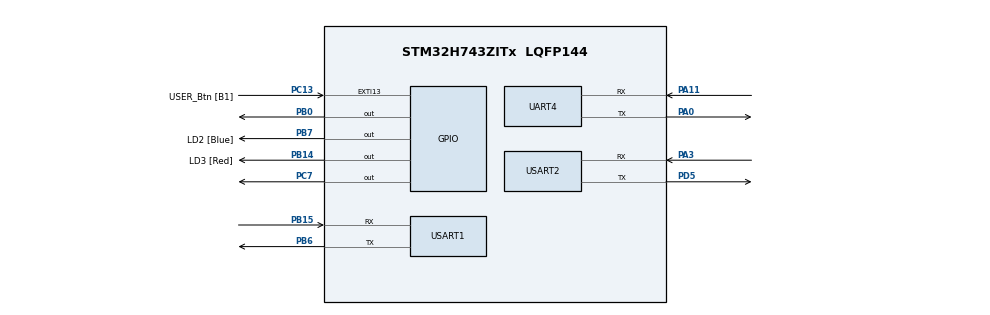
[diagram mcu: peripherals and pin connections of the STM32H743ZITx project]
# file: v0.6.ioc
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Mcu.Family=STM32H7
Mcu.Name=STM32H743ZITx
Mcu.Package=LQFP144
NVIC.PriorityGroup=NVIC_PRIORITYGROUP_4
NVIC.TIM6_DAC_IRQn=true\:0\:0\:false\:false\:true\:true\:true
NVIC.UART4_IRQn=true\:0\:0\:false\:false\:true\:true\:true
NVIC.USART1_IRQn=true\:0\:0\:false\:false\:true\:true\:true
NVIC.USART2_IRQn=true\:0\:0\:false\:false\:true\:true\:true
PA0.Mode=Asynchronous
PA0.Signal=UART4_TX
PA1.GPIO_Label=RMII_REF_CLK
PA1.Signal=ETH_REF_CLK
PA11.Mode=Asynchronous
PA11.Signal=UART4_RX
PA2.GPIO_Label=RMII_MDIO
PA2.Signal=ETH_MDIO
PA3.Mode=Asynchronous
PA3.Signal=USART2_RX
PA7.GPIO_Label=RMII_CRS_DV
PA7.Signal=ETH_CRS_DV
PB0.Signal=GPIO_Output
PB14.GPIO_Label=LD3 [Red]
PB14.Signal=GPIO_Output
PB15.Mode=Asynchronous
PB15.Signal=USART1_RX
PB6.Mode=Asynchronous
PB6.Signal=USART1_TX
PB7.GPIO_Label=LD2 [Blue]
PB7.Signal=GPIO_Output
PC1.GPIO_Label=RMII_MDC
PC1.Signal=ETH_MDC
PC13.GPIO_Label=USER_Btn [B1]
PC13.Signal=GPXTI13
PC14-OSC32_IN\ (OSC32_IN).Mode=LSE-External-Oscillator
PC14-OSC32_IN\ (OSC32_IN).Signal=RCC_OSC32_IN
PC15-OSC32_OUT\ (OSC32_OUT).Mode=LSE-External-Oscillator
PC15-OSC32_OUT\ (OSC32_OUT).Signal=RCC_OSC32_OUT
PC4.GPIO_Label=RMII_RXD0
PC4.Signal=ETH_RXD0
PC5.GPIO_Label=RMII_RXD1
PC5.Signal=ETH_RXD1
PC7.Signal=GPIO_Output
PD5.Mode=Asynchronous
PD5.Signal=USART2_TX
PD8.GPIO_Label=STLK_RX [STM32F103CBT6_PA3]
PD8.Signal=USART3_TX
PD9.GPIO_Label=STLK_TX [STM32F103CBT6_PA2]
PD9.Signal=USART3_RX
PG11.GPIO_Label=RMII_TX_EN
PG11.Signal=ETH_TX_EN
PG13.GPIO_Label=RMII_TXD0
PG13.Signal=ETH_TXD0
PH0-OSC_IN\ (PH0).GPIO_Label=MCO
PH0-OSC_IN\ (PH0).Mode=HSE-External-Clock-Source
PH0-OSC_IN\ (PH0).Signal=RCC_OSC_IN
PH1-OSC_OUT\ (PH1).Mode=HSE-External-Clock-Source
PH1-OSC_OUT\ (PH1).Signal=RCC_OSC_OUT
ProjectManager.HeapSize=0x200
ProjectManager.StackSize=0x400
ProjectManager.TargetToolchain=STM32CubeIDE
RCC.48MHZClocksFreq_Value=24000000
RCC.ADCFreq_Value=16125000
RCC.AHBFreq_Value=216000000
RCC.APB1CLKDivider=RCC_HCLK_DIV4
RCC.APB1Freq_Value=120000000
RCC.APB1TimFreq_Value=108000000
RCC.APB2CLKDivider=RCC_HCLK_DIV2
RCC.APB2Freq_Value=120000000
RCC.APB2TimFreq_Value=216000000
RCC.APB3Freq_Value=120000000
RCC.APB4Freq_Value=120000000
RCC.CortexFreq_Value=480000000
RCC.D1PPRE=RCC_APB3_DIV2
RCC.D2PPRE1=RCC_APB1_DIV2
RCC.D2PPRE2=RCC_APB2_DIV2
RCC.D3PPRE=RCC_APB4_DIV2
RCC.DIVM1=1
RCC.DIVN1=120
RCC.DIVQ1=20
RCC.HCLKFreq_Value=240000000
RCC.HPRE=RCC_HCLK_DIV2
RCC.HSE_VALUE=8000000
RCC.HSI_VALUE=64000000
RCC.PLLFRACN=0
RCC.PLLM=25
RCC.PLLMUL=RCC_PLL_MUL9
RCC.PLLN=432
RCC.PLLQ=9
RCC.PLLSourceVirtual=RCC_PLLSOURCE_HSE
RCC.PRESCALERUSB=RCC_USBCLKSOURCE_PLL_DIV1_5
RCC.PWR_Regulator_Voltage_Scale=PWR_REGULATOR_VOLTAGE_SCALE1
RCC.SYSCLKFreq_VALUE=480000000
RCC.SYSCLKSource=RCC_SYSCLKSOURCE_PLLCLK
RCC.SYSCLKSourceVirtual=RCC_SYSCLKSOURCE_PLLCLK
RCC.USBFreq_Value=48000000
RCC.VCOOutputFreq_Value=432000000
TIM6.Period=1
TIM6.Prescaler=12000
TIM6.TIM_MasterOutputTrigger=TIM_TRGO_UPDATE
USART1.VirtualMode-Asynchronous=VM_ASYNC
USART2.VirtualMode-Asynchronous=VM_ASYNC
VP_TIM6_VS_ClockSourceINT.Mode=Enable_Timer
board=NUCLEO-H743ZI

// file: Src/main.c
/* USER CODE BEGIN Header */
/**
 ******************************************************************************
 * @file           : main.c
 * @brief          : Main program body
 ******************************************************************************
 * @attention
 *
 * <h2><center>&copy; Copyright (c) 2019 STMicroelectronics.
 * All rights reserved.</center></h2>
 *
 * This software component is licensed by ST under BSD 3-Clause license,
 * the "License"; You may not use this file except in compliance with the
 * License. You may obtain a copy of the License at:
 *                        opensource.org/licenses/BSD-3-Clause
 *
 ******************************************************************************
 */
/* USER CODE END Header */

#include "main.h"

/* USER CODE BEGIN Includes */
#include "main_task.h"

/* USER CODE END Includes */

TIM_HandleTypeDef htim6;

UART_HandleTypeDef huart4;
UART_HandleTypeDef huart1;
UART_HandleTypeDef huart2;

void SystemClock_Config(void);
static void MX_GPIO_Init(void);
static void MX_TIM6_Init(void);
static void MX_USART1_UART_Init(void);
static void MX_USART2_UART_Init(void);
static void MX_UART4_Init(void);

int main(void)
{

	/* MCU Configuration--------------------------------------------------------*/

	/* Reset of all peripherals, Initializes the Flash interface and the Systick. */
	HAL_Init();

	/* Configure the system clock */
	SystemClock_Config();

	/* Initialize all configured peripherals */
	MX_GPIO_Init();
	MX_TIM6_Init();
	MX_USART1_UART_Init();
	MX_USART2_UART_Init();
	MX_UART4_Init();
	/* USER CODE BEGIN 2 */

	HAL_TIM_Base_Start_IT(&htim6);

	main_ini();

	/* USER CODE END 2 */

	/* Infinite loop */
	/* USER CODE BEGIN WHILE */
	while (1)
	{
		main_task();
		/* USER CODE END WHILE */

	}
}

void SystemClock_Config(void)
{
	RCC_OscInitTypeDef RCC_OscInitStruct = {0};
	RCC_ClkInitTypeDef RCC_ClkInitStruct = {0};
	RCC_PeriphCLKInitTypeDef PeriphClkInitStruct = {0};

	/** Supply configuration update enable
	 */
	HAL_PWREx_ConfigSupply(PWR_LDO_SUPPLY);
	/** Configure the main internal regulator output voltage
	 */
	__HAL_PWR_VOLTAGESCALING_CONFIG(PWR_REGULATOR_VOLTAGE_SCALE1);

	while(!__HAL_PWR_GET_FLAG(PWR_FLAG_VOSRDY)) {}
	/** Initializes the CPU, AHB and APB busses clocks
	 */
	RCC_OscInitStruct.OscillatorType = RCC_OSCILLATORTYPE_HSE;
	RCC_OscInitStruct.HSEState = RCC_HSE_BYPASS;
	RCC_OscInitStruct.PLL.PLLState = RCC_PLL_ON;
	RCC_OscInitStruct.PLL.PLLSource = RCC_PLLSOURCE_HSE;
	RCC_OscInitStruct.PLL.PLLM = 1;
	RCC_OscInitStruct.PLL.PLLN = 120;
	RCC_OscInitStruct.PLL.PLLP = 2;
	RCC_OscInitStruct.PLL.PLLQ = 20;
	RCC_OscInitStruct.PLL.PLLR = 2;
	RCC_OscInitStruct.PLL.PLLRGE = RCC_PLL1VCIRANGE_3;
	RCC_OscInitStruct.PLL.PLLVCOSEL = RCC_PLL1VCOWIDE;
	RCC_OscInitStruct.PLL.PLLFRACN = 0;
	if (HAL_RCC_OscConfig(&RCC_OscInitStruct) != HAL_OK)
	{
		Error_Handler();
	}
	/** Initializes the CPU, AHB and APB busses clocks
	 */
	RCC_ClkInitStruct.ClockType = RCC_CLOCKTYPE_HCLK|RCC_CLOCKTYPE_SYSCLK
			|RCC_CLOCKTYPE_PCLK1|RCC_CLOCKTYPE_PCLK2
			|RCC_CLOCKTYPE_D3PCLK1|RCC_CLOCKTYPE_D1PCLK1;
	RCC_ClkInitStruct.SYSCLKSource = RCC_SYSCLKSOURCE_PLLCLK;
	RCC_ClkInitStruct.SYSCLKDivider = RCC_SYSCLK_DIV1;
	RCC_ClkInitStruct.AHBCLKDivider = RCC_HCLK_DIV2;
	RCC_ClkInitStruct.APB3CLKDivider = RCC_APB3_DIV2;
	RCC_ClkInitStruct.APB1CLKDivider = RCC_APB1_DIV2;
	RCC_ClkInitStruct.APB2CLKDivider = RCC_APB2_DIV2;
	RCC_ClkInitStruct.APB4CLKDivider = RCC_APB4_DIV2;

	if (HAL_RCC_ClockConfig(&RCC_ClkInitStruct, FLASH_LATENCY_4) != HAL_OK)
	{
		Error_Handler();
	}
	PeriphClkInitStruct.PeriphClockSelection = RCC_PERIPHCLK_USART2|RCC_PERIPHCLK_UART4
			|RCC_PERIPHCLK_USART1;
	PeriphClkInitStruct.Usart234578ClockSelection = RCC_USART234578CLKSOURCE_D2PCLK1;
	PeriphClkInitStruct.Usart16ClockSelection = RCC_USART16CLKSOURCE_D2PCLK2;
	if (HAL_RCCEx_PeriphCLKConfig(&PeriphClkInitStruct) != HAL_OK)
	{
		Error_Handler();
	}
}

static void MX_TIM6_Init(void)
{

	TIM_MasterConfigTypeDef sMasterConfig = {0};

	htim6.Instance = TIM6;
	htim6.Init.Prescaler = 12000;
	htim6.Init.CounterMode = TIM_COUNTERMODE_UP;
	htim6.Init.Period = 1;
	htim6.Init.AutoReloadPreload = TIM_AUTORELOAD_PRELOAD_DISABLE;
	if (HAL_TIM_Base_Init(&htim6) != HAL_OK)
	{
		Error_Handler();
	}
	sMasterConfig.MasterOutputTrigger = TIM_TRGO_UPDATE;
	sMasterConfig.MasterSlaveMode = TIM_MASTERSLAVEMODE_DISABLE;
	if (HAL_TIMEx_MasterConfigSynchronization(&htim6, &sMasterConfig) != HAL_OK)
	{
		Error_Handler();
	}

}

static void MX_UART4_Init(void)
{

	huart4.Instance = UART4;
	huart4.Init.BaudRate = 115200;
	huart4.Init.WordLength = UART_WORDLENGTH_8B;
	huart4.Init.StopBits = UART_STOPBITS_1;
	huart4.Init.Parity = UART_PARITY_NONE;
	huart4.Init.Mode = UART_MODE_TX_RX;
	huart4.Init.HwFlowCtl = UART_HWCONTROL_NONE;
	huart4.Init.OverSampling = UART_OVERSAMPLING_16;
	huart4.Init.OneBitSampling = UART_ONE_BIT_SAMPLE_DISABLE;
	huart4.Init.ClockPrescaler = UART_PRESCALER_DIV1;
	huart4.AdvancedInit.AdvFeatureInit = UART_ADVFEATURE_NO_INIT;
	if (HAL_UART_Init(&huart4) != HAL_OK)
	{
		Error_Handler();
	}
	if (HAL_UARTEx_SetTxFifoThreshold(&huart4, UART_TXFIFO_THRESHOLD_1_8) != HAL_OK)
	{
		Error_Handler();
	}
	if (HAL_UARTEx_SetRxFifoThreshold(&huart4, UART_RXFIFO_THRESHOLD_1_8) != HAL_OK)
	{
		Error_Handler();
	}
	if (HAL_UARTEx_DisableFifoMode(&huart4) != HAL_OK)
	{
		Error_Handler();
	}

}

static void MX_USART1_UART_Init(void)
{

	huart1.Instance = USART1;
	huart1.Init.BaudRate = 115200;
	huart1.Init.WordLength = UART_WORDLENGTH_8B;
	huart1.Init.StopBits = UART_STOPBITS_1;
	huart1.Init.Parity = UART_PARITY_NONE;
	huart1.Init.Mode = UART_MODE_TX_RX;
	huart1.Init.HwFlowCtl = UART_HWCONTROL_NONE;
	huart1.Init.OverSampling = UART_OVERSAMPLING_16;
	huart1.Init.OneBitSampling = UART_ONE_BIT_SAMPLE_DISABLE;
	huart1.Init.ClockPrescaler = UART_PRESCALER_DIV1;
	huart1.AdvancedInit.AdvFeatureInit = UART_ADVFEATURE_NO_INIT;
	if (HAL_UART_Init(&huart1) != HAL_OK)
	{
		Error_Handler();
	}
	if (HAL_UARTEx_SetTxFifoThreshold(&huart1, UART_TXFIFO_THRESHOLD_1_8) != HAL_OK)
	{
		Error_Handler();
	}
	if (HAL_UARTEx_SetRxFifoThreshold(&huart1, UART_RXFIFO_THRESHOLD_1_8) != HAL_OK)
	{
		Error_Handler();
	}
	if (HAL_UARTEx_DisableFifoMode(&huart1) != HAL_OK)
	{
		Error_Handler();
	}

}

static void MX_USART2_UART_Init(void)
{

	huart2.Instance = USART2;
	huart2.Init.BaudRate = 115200;
	huart2.Init.WordLength = UART_WORDLENGTH_8B;
	huart2.Init.StopBits = UART_STOPBITS_1;
	huart2.Init.Parity = UART_PARITY_NONE;
	huart2.Init.Mode = UART_MODE_TX_RX;
	huart2.Init.HwFlowCtl = UART_HWCONTROL_NONE;
	huart2.Init.OverSampling = UART_OVERSAMPLING_16;
	huart2.Init.OneBitSampling = UART_ONE_BIT_SAMPLE_DISABLE;
	huart2.Init.ClockPrescaler = UART_PRESCALER_DIV1;
	huart2.AdvancedInit.AdvFeatureInit = UART_ADVFEATURE_NO_INIT;
	if (HAL_UART_Init(&huart2) != HAL_OK)
	{
		Error_Handler();
	}
	if (HAL_UARTEx_SetTxFifoThreshold(&huart2, UART_TXFIFO_THRESHOLD_1_8) != HAL_OK)
	{
		Error_Handler();
	}
	if (HAL_UARTEx_SetRxFifoThreshold(&huart2, UART_RXFIFO_THRESHOLD_1_8) != HAL_OK)
	{
		Error_Handler();
	}
	if (HAL_UARTEx_DisableFifoMode(&huart2) != HAL_OK)
	{
		Error_Handler();
	}

}

static void MX_GPIO_Init(void)
{
	GPIO_InitTypeDef GPIO_InitStruct = {0};

	/* GPIO Ports Clock Enable */
	__HAL_RCC_GPIOC_CLK_ENABLE();
	__HAL_RCC_GPIOH_CLK_ENABLE();
	__HAL_RCC_GPIOA_CLK_ENABLE();
	__HAL_RCC_GPIOB_CLK_ENABLE();
	__HAL_RCC_GPIOD_CLK_ENABLE();
	__HAL_RCC_GPIOG_CLK_ENABLE();

	/*Configure GPIO pin Output Level */
	HAL_GPIO_WritePin(GPIOB, GPIO_PIN_0|LD3_Pin|LD2_Pin, GPIO_PIN_RESET);

	/*Configure GPIO pin Output Level */
	HAL_GPIO_WritePin(GPIOC, GPIO_PIN_7, GPIO_PIN_RESET);

	/*Configure GPIO pin : USER_Btn_Pin */
	GPIO_InitStruct.Pin = USER_Btn_Pin;
	GPIO_InitStruct.Mode = GPIO_MODE_IT_RISING;
	GPIO_InitStruct.Pull = GPIO_NOPULL;
	HAL_GPIO_Init(USER_Btn_GPIO_Port, &GPIO_InitStruct);

	/*Configure GPIO pins : RMII_MDC_Pin RMII_RXD0_Pin RMII_RXD1_Pin */
	GPIO_InitStruct.Pin = RMII_MDC_Pin|RMII_RXD0_Pin|RMII_RXD1_Pin;
	GPIO_InitStruct.Mode = GPIO_MODE_AF_PP;
	GPIO_InitStruct.Pull = GPIO_NOPULL;
	GPIO_InitStruct.Speed = GPIO_SPEED_FREQ_LOW;
	GPIO_InitStruct.Alternate = GPIO_AF11_ETH;
	HAL_GPIO_Init(GPIOC, &GPIO_InitStruct);

	/*Configure GPIO pins : RMII_REF_CLK_Pin RMII_MDIO_Pin RMII_CRS_DV_Pin */
	GPIO_InitStruct.Pin = RMII_REF_CLK_Pin|RMII_MDIO_Pin|RMII_CRS_DV_Pin;
	GPIO_InitStruct.Mode = GPIO_MODE_AF_PP;
	GPIO_InitStruct.Pull = GPIO_NOPULL;
	GPIO_InitStruct.Speed = GPIO_SPEED_FREQ_LOW;
	GPIO_InitStruct.Alternate = GPIO_AF11_ETH;
	HAL_GPIO_Init(GPIOA, &GPIO_InitStruct);

	/*Configure GPIO pins : PB0 LD3_Pin LD2_Pin */
	GPIO_InitStruct.Pin = GPIO_PIN_0|LD3_Pin|LD2_Pin;
	GPIO_InitStruct.Mode = GPIO_MODE_OUTPUT_PP;
	GPIO_InitStruct.Pull = GPIO_NOPULL;
	GPIO_InitStruct.Speed = GPIO_SPEED_FREQ_LOW;
	HAL_GPIO_Init(GPIOB, &GPIO_InitStruct);

	/*Configure GPIO pins : STLK_RX_Pin STLK_TX_Pin */
	GPIO_InitStruct.Pin = STLK_RX_Pin|STLK_TX_Pin;
	GPIO_InitStruct.Mode = GPIO_MODE_AF_PP;
	GPIO_InitStruct.Pull = GPIO_NOPULL;
	GPIO_InitStruct.Speed = GPIO_SPEED_FREQ_LOW;
	GPIO_InitStruct.Alternate = GPIO_AF7_USART3;
	HAL_GPIO_Init(GPIOD, &GPIO_InitStruct);

	/*Configure GPIO pin : PC7 */
	GPIO_InitStruct.Pin = GPIO_PIN_7;
	GPIO_InitStruct.Mode = GPIO_MODE_OUTPUT_PP;
	GPIO_InitStruct.Pull = GPIO_NOPULL;
	GPIO_InitStruct.Speed = GPIO_SPEED_FREQ_LOW;
	HAL_GPIO_Init(GPIOC, &GPIO_InitStruct);

	/*Configure GPIO pins : RMII_TX_EN_Pin RMII_TXD0_Pin */
	GPIO_InitStruct.Pin = RMII_TX_EN_Pin|RMII_TXD0_Pin;
	GPIO_InitStruct.Mode = GPIO_MODE_AF_PP;
	GPIO_InitStruct.Pull = GPIO_NOPULL;
	GPIO_InitStruct.Speed = GPIO_SPEED_FREQ_LOW;
	GPIO_InitStruct.Alternate = GPIO_AF11_ETH;
	HAL_GPIO_Init(GPIOG, &GPIO_InitStruct);

}

void Error_Handler(void)
{
}

/************************ (C) COPYRIGHT STMicroelectronics *****END OF FILE****/
